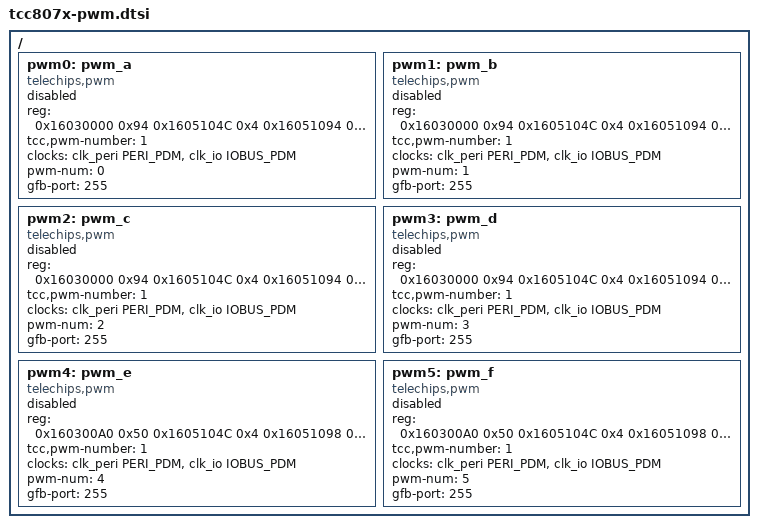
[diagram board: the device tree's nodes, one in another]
// SPDX-License-Identifier: (GPL-2.0-or-later OR MIT)
/*
 * Copyright (C) 2023 Telechips Inc.
 */

#include <dt-bindings/clock/telechips,tcc807x-clks.h>

/ {
	pwm0: pwm_a {
		compatible = "telechips,pwm";
		reg = <0x16030000 0x94 0x1605104C 0x4 0x16051094 0x4>;
		tcc,pwm-number = <1>;
		#pwm-cells = <2>;
		clocks = <&clk_peri PERI_PDM &clk_io IOBUS_PDM>;
		pwm-num = <0>;
		gfb-port = <255>;
		status = "disabled";
	};
	pwm1: pwm_b {
		compatible = "telechips,pwm";
		reg = <0x16030000 0x94 0x1605104C 0x4 0x16051094 0x4>;
		tcc,pwm-number = <1>;
		#pwm-cells = <2>;
		clocks = <&clk_peri PERI_PDM &clk_io IOBUS_PDM>;
		pwm-num = <1>;
		gfb-port = <255>;
		status = "disabled";
	};
	pwm2: pwm_c {
		compatible = "telechips,pwm";
		reg = <0x16030000 0x94 0x1605104C 0x4 0x16051094 0x4>;
		tcc,pwm-number = <1>;
		#pwm-cells = <2>;
		clocks = <&clk_peri PERI_PDM &clk_io IOBUS_PDM>;
		pwm-num = <2>;
		gfb-port = <255>;
		status = "disabled";
	};
	pwm3: pwm_d {
		compatible = "telechips,pwm";
		reg = <0x16030000 0x94 0x1605104C 0x4 0x16051094 0x4>;
		tcc,pwm-number = <1>;
		#pwm-cells = <2>;
		clocks = <&clk_peri PERI_PDM &clk_io IOBUS_PDM>;
		pwm-num = <3>;
		gfb-port = <255>;
		status = "disabled";
	};
	pwm4: pwm_e {
		compatible = "telechips,pwm";
		reg = <0x160300A0 0x50 0x1605104C 0x4 0x16051098 0x4>;
		tcc,pwm-number = <1>;
		#pwm-cells = <2>;
		clocks = <&clk_peri PERI_PDM &clk_io IOBUS_PDM>;
		pwm-num = <4>;
		gfb-port = <255>;
		status = "disabled";
	};
	pwm5: pwm_f {
		compatible = "telechips,pwm";
		reg = <0x160300A0 0x50 0x1605104C 0x4 0x16051098 0x4>;
		tcc,pwm-number = <1>;
		#pwm-cells = <2>;
		clocks = <&clk_peri PERI_PDM &clk_io IOBUS_PDM>;
		pwm-num = <5>;
		gfb-port = <255>;
		status = "disabled";
	};
};
